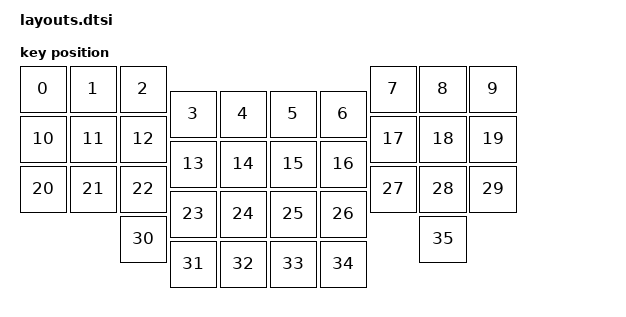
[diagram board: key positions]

#include <physical_layouts.dtsi>
/ {
    physical_layout0: physical_layout0 {
        compatible = "zmk,physical-layout";
        display-name = "Layout";
        keys
            = <&key_physical_attrs 100 100 0 0 0 0 0>
			,<&key_physical_attrs 100 100 100 0 0 0 0>
			,<&key_physical_attrs 100 100 200 0 0 0 0>
			,<&key_physical_attrs 100 100 300 50 0 0 0>
			,<&key_physical_attrs 100 100 400 50 0 0 0>
			,<&key_physical_attrs 100 100 500 50 0 0 0>
			,<&key_physical_attrs 100 100 600 50 0 0 0>
			,<&key_physical_attrs 100 100 700 0 0 0 0>
			,<&key_physical_attrs 100 100 800 0 0 0 0>
			,<&key_physical_attrs 100 100 900 0 0 0 0>
			,<&key_physical_attrs 100 100 0 100 0 0 0>
			,<&key_physical_attrs 100 100 100 100 0 0 0>
			,<&key_physical_attrs 100 100 200 100 0 0 0>
			,<&key_physical_attrs 100 100 300 150 0 0 0>
			,<&key_physical_attrs 100 100 400 150 0 0 0>
			,<&key_physical_attrs 100 100 500 150 0 0 0>
			,<&key_physical_attrs 100 100 600 150 0 0 0>
			,<&key_physical_attrs 100 100 700 100 0 0 0>
			,<&key_physical_attrs 100 100 800 100 0 0 0>
			,<&key_physical_attrs 100 100 900 100 0 0 0>
			,<&key_physical_attrs 100 100 0 200 0 0 0>
			,<&key_physical_attrs 100 100 100 200 0 0 0>
			,<&key_physical_attrs 100 100 200 200 0 0 0>
			,<&key_physical_attrs 100 100 300 250 0 0 0>
			,<&key_physical_attrs 100 100 400 250 0 0 0>
			,<&key_physical_attrs 100 100 500 250 0 0 0>
			,<&key_physical_attrs 100 100 600 250 0 0 0>
			,<&key_physical_attrs 100 100 700 200 0 0 0>
			,<&key_physical_attrs 100 100 800 200 0 0 0>
			,<&key_physical_attrs 100 100 900 200 0 0 0>
			,<&key_physical_attrs 100 100 200 300 0 0 0>
			,<&key_physical_attrs 100 100 300 350 0 0 0>
			,<&key_physical_attrs 100 100 400 350 0 0 0>
			,<&key_physical_attrs 100 100 500 350 0 0 0>
			,<&key_physical_attrs 100 100 600 350 0 0 0>
			,<&key_physical_attrs 100 100 800 300 0 0 0>
            ;
    };
};
